# CAMERARX0 register map
Vendor: Texas Instruments
Peripheral module from a debugger description file (folder am65x).
Registers are 32-bit, read-write, reset 0x0 unless marked. A register's access mark holds for its fields unless they carry their own. Offsets are as the file gives them; lines under a group give offsets from that group; [hi:lo] are bit positions; {n}, {i} and the like mark numbered series; 'fields as' and 'values as' point back to an identical list; <NAME> marks a mode.

## CAMERARX0
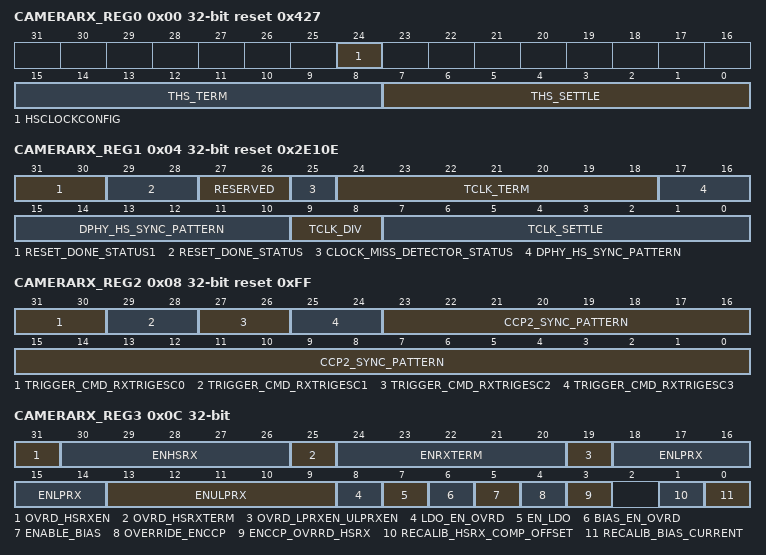
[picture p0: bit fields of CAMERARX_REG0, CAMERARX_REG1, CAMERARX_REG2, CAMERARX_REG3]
0x00 CAMERARX_REG0 access per field reset 0x427 — First Register
  [24] HSCLOCKCONFIG rw — Disable clock missing detector
  [15:8] THS_TERM rw — Ths-Term timing parameter in multiples of DDR clock. Requirement from D-PHY spec = (Dn Voltage &lt; 450 mV) - 35 ns+ 4UI. Effective time for enabling of termination = synchronizer delay + timer delay + LPRX delay + combinational routing delay. ~ (1-2) * DDRCLK + THS-TERM + ~ (1-15)ns Programmed Value = ceil (12.5 / DDR Clock period) - 1 Default value : 4 (for 400 MHz) Note: +/- 20% clock frequency tolerance
  [7:0] THS_SETTLE rw — THS-Settle timing parameter in multiples of DDR clock frequency. Derived requirement from D-PHY spec = (90ns + 6UI) - (145ns + 10UI). Effective Ths-settle seen on line (starting to look for sync pattern) = synchronizer delay + timer delay + LPRX delay + combinational routing delay - pipeline delay in HS data path. ~ (1-2)* DDRCLK + THS-SETTLE + ~ (1-15)ns - 1*DDRCLK Programmed Value = ceil (90ns / DDR Clock Period) + 3 Default value : 39 (for 400 MHz) Note: (i) Minimum supported THS-SETTLE programmed value = 3 (ii) One clock delay in datapath from HSRX also needs to be compensated. Hence +3
0x04 CAMERARX_REG1 access per field reset 0x2E10E — Second Register
  [31:30] RESET_DONE_STATUS1 ro — Reset done read bits
  [29:28] RESET_DONE_STATUS ro — Reset done read bits. 28: RESETDONERXBYTECLK 29: RESETDONECTRLCLK
  [27:26] RESERVED rw — Write 0 for future compatibility
  [25] CLOCK_MISS_DETECTOR_STATUS ro — Clock missing detector status. Internal debug bit. 1: Error in clock missing detector. 0: Clock missing detector successful Note: CLKMISS detector is likely to malfunction, if tclk-trail spec (60ns) is not honoured.
  [24:18] TCLK_TERM rw — TCLK_TERM timing parameter in multiples of CTRLCLK. Requirement from D-PHY spec = (Dn Voltage &lt; 450 mV) - 38 ns. Effective time for enabling of termination = synchronizer delay + timer delay + LPRX delay + combinational routing delay. ~ (1-2)* CTRLCLK + TCLK_TERM + ~ (1-15)ns Programmed Value = ceil (9.5 / CTRLCLK Period) - 1 Default value : 0 (for 96 MHz) Note: +/- 5% clock frequency tolerance
  [17:10] DPHY_HS_SYNC_PATTERN rw — DPHY mode HS sync pattern in byte order (reverse of received order). D-PHY mode sync pattern. Default : '10111000'
  [9:8] TCLK_DIV rw — CTRLCLK_DIV_FACTOR. Divide factor for CTRLCLK for CLKMISS detector. Programmed value = ceil (15ns / CTRLCLK Period) - 1 Default value: 1 (for 96 MHz) CLKMISS detection time = (5*DIV+1)*(CTRLCLK period) &lt; 60ns Note: Only the CTRLCLK frequencies that satisfies above relationship are allowed. Typically 96MHz should always be used at CTRLCLK.
  [7:0] TCLK_SETTLE rw — TClk_Settle timing parameter in multiples of DDR Clock. Derived requirement from D-PHY spec = 100ns-300ns. Effective Ths-settle = synchronizer delay + timer delay + LPRX delay + combinational routing delay ~ (1-2)* CTRLCLK + Tclk-settle + ~ (1-15)ns Programmed Value = max (3, ceil (155ns/CTRLCLK Period)) Default value: 14 (for 96 MHz) Note: +/- 5% clock frequency tolerance
0x08 CAMERARX_REG2 reset 0xFF — Third register
  [31:30] TRIGGER_CMD_RXTRIGESC0 — Mapping of Trigger escape entry command to PPI output RXTRIGGERESC0 00: '01100010' 01: '01011101' 10: '00100001' 11: '10100000'
  [29:28] TRIGGER_CMD_RXTRIGESC1 — Mapping of Trigger escape entry command to PPI output RXTRIGGERESC1 00: '01011101' 01: '00100001' 10: '10100000' 11: '01100010'
  [27:26] TRIGGER_CMD_RXTRIGESC2 — Mapping of Trigger escape entry command to PPI output RXTRIGGERESC2 00: '00100001' 01: '01100010' 10: '01100010' 11: '01011101'
  [25:24] TRIGGER_CMD_RXTRIGESC3 — Mapping of Trigger escape entry command to PPI output RXTRIGGERESC3 00: '10100000' 01: '01100010' 10: '01011101' 11: '00100001'
  [23:0] CCP2_SYNC_PATTERN — CCP2 mode sync pattern in byte order (reverse of received order)
0x0C CAMERARX_REG3 access per field — Fourth Register
  [31] OVRD_HSRXEN rw — 1: Override. 0: Default
  [30:26] ENHSRX rw — HSRX Enable on LANE 5-0. 1: Enable. 0: Disable
  [25] OVRD_HSRXTERM rw — Override with register bit. 1: Override. 0: Default
  [24:20] ENRXTERM rw — HS-RX Termination enable on LANE 5-0. 1: Enable. 0: Default
  [19] OVRD_LPRXEN_ULPRXEN rw — Override LP-RX and ULP-RX Enable. 1: Override. 0: Default
  [18:14] ENLPRX rw — Enable for LP-RX on LANE 5-0 1: Enable 0: Disable
  [13:9] ENULPRX rw — Enable for ULP-RX on LANE 5-0 1: Enable 0: Disable
  [8] LDO_EN_OVRD rw — LDO Enable Override. 1: Override. 0: Default
  [7] EN_LDO rw — Enable LDO. 1: Enable. 0: Default
  [6] BIAS_EN_OVRD rw — BIAS Enable Override. 1: Override with register bit. 0: Default
  [5] ENABLE_BIAS rw — Enable BIAS. 1: Enable 0: Disable
  [4] OVERRIDE_ENCCP rw — Override ENCCP to anatop. 1: Override with register bit 0: Default
  [3] ENCCP_OVRRD_HSRX rw — ENCCP override to HSRX. 1: Enable 0: Disable
  [1] RECALIB_HSRX_COMP_OFFSET rw — Recalibrate HS-RX comparator offset. Make this bit 0'1 to restart offset calibration. Usually offset calibration happens after PWRCMDON is received.
  [0] RECALIB_BIAS_CURRENT rw — Recalibrate biasgen. Make this bit 0'1 to restart bias calibration. Biasgen trim code in efuse is overridden with new calibrated value till this bit is '1'.
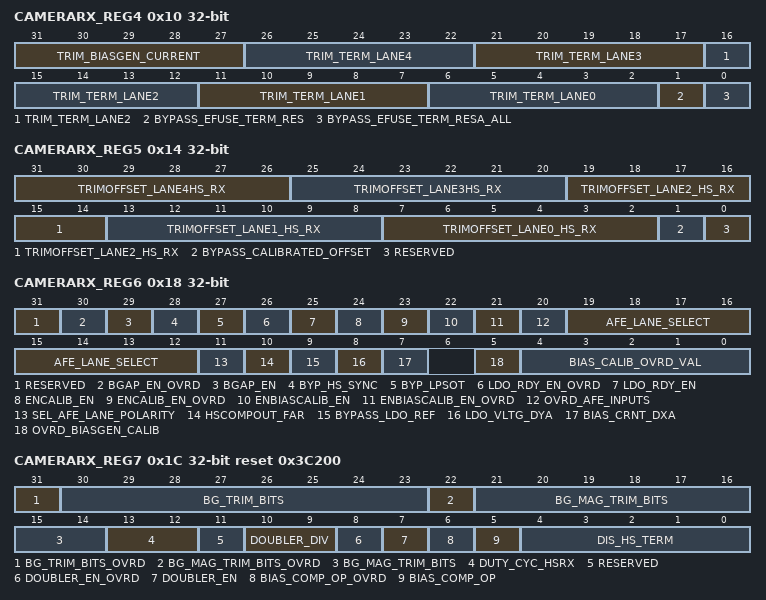
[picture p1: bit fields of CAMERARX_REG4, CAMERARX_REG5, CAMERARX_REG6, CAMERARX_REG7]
0x10 CAMERARX_REG4 — Fifth Register
  [31:27] TRIM_BIASGEN_CURRENT
  [5n+6:5n+2] TRIM_TERM_LANE{n} (n=0..4) — Trim termination resistor of lane {n}
  [1] BYPASS_EFUSE_TERM_RES — Bypass efuse bits for termination resistor. 1: Bypass EFUSE bits 0: Use EFUSE bits
  [0] BYPASS_EFUSE_TERM_RESA_ALL — Trim Termination resistor of all Lanes 1: overrides all restrim codes to same code from SCP register 4 bits [6:2], instead of individual control for individual bits. 0: Default
0x14 CAMERARX_REG5 — Sixth Register
  [31:26] TRIMOFFSET_LANE4HS_RX — Trim Offset of Lane4 HS-RX. Sign Magnitude Trim code.
  [25:20] TRIMOFFSET_LANE3HS_RX — Trim Offset of Lane3 HS-RX. Sign Magnitude Trim code.
  [19:14] TRIMOFFSET_LANE2_HS_RX — Trim Offset of Lane2 HS-RX. Sign Magnitude Trim code.
  [13:8] TRIMOFFSET_LANE1_HS_RX — Trim Offset of Lane1 HS-RX. Sign Magnitude Trim code.
  [7:2] TRIMOFFSET_LANE0_HS_RX — Trim Offset of Lane0 HS-RX. Sign Magnitude Trim code.
  [1] BYPASS_CALIBRATED_OFFSET — 1: Bypass the calibrated offset 0: Donot bypass
  [0] RESERVED — Wrire 0 for future compatibility
0x18 CAMERARX_REG6 access per field — Seventh Register
  [31] RESERVED rw — Write 0 for future compatibility
  [30] BGAP_EN_OVRD rw — BGAP enable override 0: Default 1: Override bandgap enable with following register bit
  [29] BGAP_EN rw — BANDGAP enable 0: Disable 1: enable
  [28] BYP_HS_SYNC rw — To bypass HS Sync sequence 0: Normal 1: Bypass the HS Sync sequence
  [27] BYP_LPSOT rw — To bypass the LP SoT sequence in loopback mode 0: Normal 1: Bypass the LP SoT sequence
  [26] LDO_RDY_EN_OVRD rw — LDO_RDY override 0: Default 1: Override LDO_RDY with the following register bit
  [25] LDO_RDY_EN rw — LDO_RDY makes internal LDO_RDY=1
  [24] ENCALIB_EN rw — ENCALIBA and ENCALIBB
  [23] ENCALIB_EN_OVRD rw — ENCALIB override 0: Default 1: Override ENCALIBA and ENCALIBB with following register bit
  [22] ENBIASCALIB_EN rw — ENBIASCALIB
  [21] ENBIASCALIB_EN_OVRD rw — ENBIASCALIB override 0: Default 1: Override ENBIASCALIB with following register bit
  [20] OVRD_AFE_INPUTS rw — Override LANEENABLE and POLARITY AFE inputs. 0:Normal. 1:Override
  [19:12] AFE_LANE_SELECT rw — Selects clock lane and data lane mapping for AFE. 8 bit LANESEL for AFE
  [11] SEL_AFE_LANE_POLARITY rw — Select AFE lane polarity. Polarity for clock lane in AFE
  [10] HSCOMPOUT_FAR rw — Select FAR lane HSCOMP output to HSCOMOOUT in AFE.
  [9] BYPASS_LDO_REF rw — 0:Normal. 1:Bypass reference with VDD
  [8] LDO_VLTG_DYA rw — Observe LDO voltage on DYA pad. 0:Normal. 1:Observe LDO voltage
  [7] BIAS_CRNT_DXA rw — Observe bias current on DXA pad. 0:Normal. 1:Observe bias current
  [5] OVRD_BIASGEN_CALIB rw — 1:Override the EFUSE bits with register value. 0:Default
  [4:0] BIAS_CALIB_OVRD_VAL rw — Biasgen calibration code override value
0x1C CAMERARX_REG7 reset 0x3C200 — Eigth register
  [31] BG_TRIM_BITS_OVRD — Bandgap trim bits override 0: Normal (default mode) 1: Override Bandgap trim bits with SCP register bits
  [30:23] BG_TRIM_BITS — Bandgap trim bitsBandgap trim bits 00000000: Minimum bandgap voltage 11111111: Maximum bandgap voltage
  [22] BG_MAG_TRIM_BITS_OVRD — Bandgap magnitude trim bits override Bandgap magnitude trim bits override 0: Normal (default mode) 1: Override Bandgap trim bits with SCP register bits
  [21:14] BG_MAG_TRIM_BITS — Bandgap magnitude trim bits 00000000: Minimum bandgap voltage 11111111: Maximum bandgap voltage
  [13:12] DUTY_CYC_HSRX — Duty cycle measurement in HSRX mode 00: Default 11: Reserved
  [11] RESERVED — Write 0 for future compatibility
  [10:9] DOUBLER_DIV — 2 bit for doubler programmable div: 00 - No division 01 - Div2 10 - Div3 11 - Div4 Default: 01 - Div2 selected since CTRLCLK is 96Mhz and doubler clk req is 48Mhz
  [8] DOUBLER_EN_OVRD — Doubler enable override from bit 7
  [7] DOUBLER_EN — Doubler enable from this bit
  [6] BIAS_COMP_OP_OVRD — BIASCALIB override 0: Default 1: Override BIASCALIB with the register bit[5]
  [5] BIAS_COMP_OP — BIASCALIB bit from SCP reg
  [4:0] DIS_HS_TERM — Disable HS Termination 00000: Normal 11111: Disable Lane4,3,2,1,0 resp
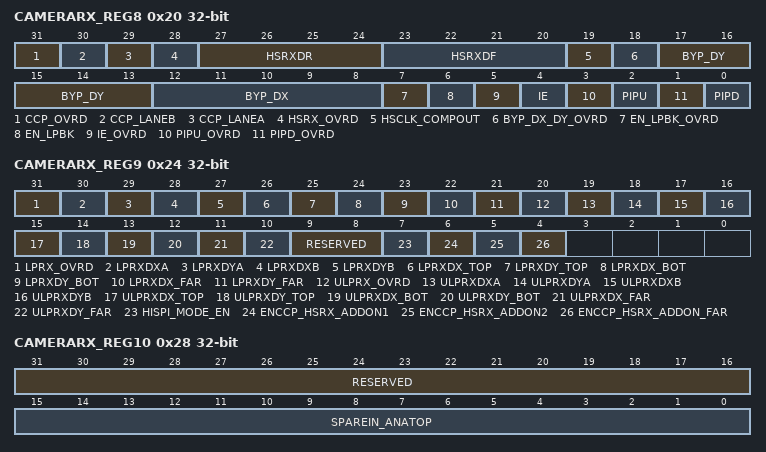
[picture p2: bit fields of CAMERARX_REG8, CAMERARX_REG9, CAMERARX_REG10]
0x20 CAMERARX_REG8 — Ninth register
  [31] CCP_OVRD — CCP override 0: Normal 1: Override CCP outputs with the register bits
  [30] CCP_LANEB — CCPF Override CCPF from analog with this register bit
  [29] CCP_LANEA — CCPR Override CCPR from analog with this register bit
  [28] HSRX_OVRD — HSRX override 0: Normal 1: Override HSRX signals with the following register bits
  [27:24] HSRXDR — CSI2R[3:0] Override CSI2R [3:0] for 4 lanes from analog with these register bits
  [23:20] HSRXDF — CSI2F[3:0] Override CSI2F [3:0] for 4 lanes from analog with these register bits
  [19] HSCLK_COMPOUT — HSCOMPOUT
  [18] BYP_DX_DY_OVRD — SELDX*/Y* override 0: Overrides the control to bypass of LPRX delay on DX/DY pads depending on testmode_sel_reg[6] and WPI_PMT[0] for DX pads and WPI_PMT[1] for DY pads. 1: Override the control to bypass the LPRX delay on DY/DX pads with the following register bits for all lanes
  [17:13] BYP_DY — SELDY* controls bypass of LPRX delay on DY pads (5 lanes) Bit Mapping: 17 -&gt; ADDON3 16 -&gt; ADDON2 15 -&gt; LaneB 14 -&gt; LaneA 13 -&gt; ADDON1
  [12:8] BYP_DX — SELDX* controls bypass of LPRX delay on DX pads (5 lanes) Bit Mapping: 12 -&gt; ADDON3 11 -&gt; ADDON2 10 -&gt; LaneB 9 -&gt; LaneA 8 -&gt; ADDON1
  [7] EN_LPBK_OVRD — ENLOOPBACK Override 0: Normal 1: Override ENLOOPBACK transmitter enable (in self or internal loopback mode) with register bit[6]
  [6] EN_LPBK — ENLOOPBACK transmitter enable (in self or internal loopback mode) from SCP register bit
  [5] IE_OVRD — IE override 0: Normal 1: Override IE (4 lanes) with the following register bit
  [4] IE — IE [3:0] Override IE [3:0] (4 lanes) with this single bit.
  [3] PIPU_OVRD — PIPU override 0: Normal 1: Override PIPU (4 lanes) with the following register bit
  [2] PIPU — PIPU [3:0] Override PIPU [3:0] (4 lanes) with this single bit.
  [1] PIPD_OVRD — PIPD override 0: Normal 1: Override PIPD (4 lanes) with the following register bit
  [0] PIPD — PIPD [3:0] Override PIPD [3:0] (4 lanes) with this single bit.
0x24 CAMERARX_REG9 — Tenth register
  [31] LPRX_OVRD — LPRX override 0: Normal (defautlt mode) 1: Override the LPRXD* signals with SCP register bits
  [30] LPRXDXA — Bypass LPRXD* comparator output with this bit
  [29] LPRXDYA — Bypass LPRXD* comparator output with this bit
  [28] LPRXDXB — Bypass LPRXD* comparator output with this bit
  [27] LPRXDYB — Bypass LPRXD* comparator output with this bit
  [26] LPRXDX_TOP — Bypass LPRXD* comparator output with this bit
  [25] LPRXDY_TOP — Bypass LPRXD* comparator output with this bit
  [24] LPRXDX_BOT — Bypass LPRXD* comparator output with this bit
  [23] LPRXDY_BOT — Bypass LPRXD* comparator output with this bit
  [22] LPRXDX_FAR — Bypass LPRXD* comparator output with this bit
  [21] LPRXDY_FAR — Bypass LPRXD* comparator output with this bit
  [20] ULPRX_OVRD — ULPRX Override 0: Normal (default mode) 1: Override the ULPRXD* signals with SCP register bits
  [19] ULPRXDXA — Bypass ULPRXD* comparator output with this bit
  [18] ULPRXDYA — Bypass ULPRXD* comparator output with this bit
  [17] ULPRXDXB — Bypass ULPRXD* comparator output with this bit
  [16] ULPRXDYB — Bypass ULPRXD* comparator output with this bit
  [15] ULPRXDX_TOP — Bypass ULPRXD* comparator output with this bit
  [14] ULPRXDY_TOP — Bypass ULPRXD* comparator output with this bit
  [13] ULPRXDX_BOT — Bypass ULPRXD* comparator output with this bit
  [12] ULPRXDY_BOT — Bypass ULPRXD* comparator output with this bit
  [11] ULPRXDX_FAR — Bypass ULPRXD* comparator output with this bit
  [10] ULPRXDY_FAR — Bypass ULPRXD* comparator output with this bit
  [9:8] RESERVED — Write 0 for future compatibility
  [7] HISPI_MODE_EN — This bit enables the PHY in HiSPi mode. 0: HiSPi mode disabled (Default) 1: HiSPI mode enabled
  [6] ENCCP_HSRX_ADDON1 — ENCCP override to HSRX of ADDON1. 1: Enable 0: Disable
  [5] ENCCP_HSRX_ADDON2 — ENCCP override to HSRX of ADDON2. 1: Enable 0: Disable
  [4] ENCCP_HSRX_ADDON_FAR — ENCCP override to HSRX of ADDON_FAR. 1: Enable 0: Disable
0x28 CAMERARX_REG10 access per field — Eleventh register
  [31:16] RESERVED ro — Read returns 0
  [15:0] SPAREIN_ANATOP rw — Sparein Anatop. These bits are directly mapped to SPAREIN* pins of Analog (both LDO and Core voltage domains) and ADDONs for future use.
